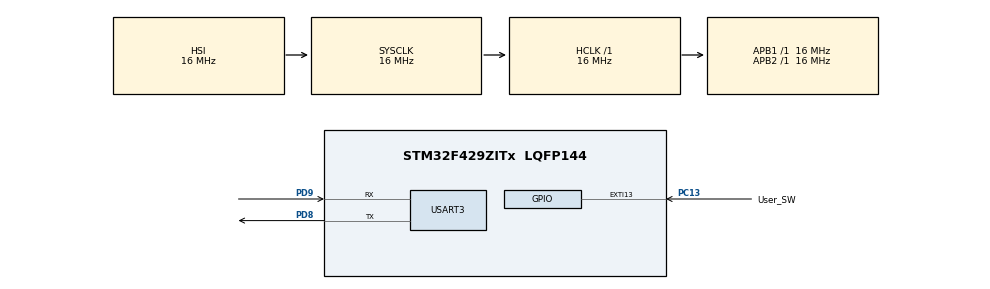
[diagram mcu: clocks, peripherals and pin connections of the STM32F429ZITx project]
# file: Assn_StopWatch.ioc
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Mcu.Family=STM32F4
Mcu.Name=STM32F429ZITx
Mcu.Package=LQFP144
NVIC.EXTI15_10_IRQn=true\:0\:0\:false\:true\:true\:2\:true\:true\:true
NVIC.PriorityGroup=NVIC_PRIORITYGROUP_4
NVIC.TIM3_IRQn=true\:0\:0\:false\:true\:true\:3\:true\:true\:true
NVIC.TIM4_IRQn=true\:0\:0\:false\:true\:true\:4\:true\:true\:true
NVIC.USART3_IRQn=true\:0\:0\:false\:true\:true\:1\:true\:true\:true
PC13.GPIO_Label=User_SW
PC13.Signal=GPXTI13
PD8.Mode=Asynchronous
PD8.Signal=USART3_TX
PD9.Mode=Asynchronous
PD9.Signal=USART3_RX
ProjectManager.HeapSize=0x200
ProjectManager.StackSize=0x400
ProjectManager.TargetToolchain=STM32CubeIDE
RCC.AHBFreq_Value=16000000
RCC.APB1Freq_Value=16000000
RCC.APB2Freq_Value=16000000
RCC.CortexFreq_Value=16000000
RCC.HSE_VALUE=25000000
RCC.HSI_VALUE=16000000
RCC.LSE_VALUE=32768
RCC.SYSCLKFreq_VALUE=16000000
RCC.VCOOutputFreq_Value=192000000
TIM3.Period=9
TIM3.Prescaler=15999
TIM4.Period=999
TIM4.Prescaler=15999
USART3.VirtualMode=VM_ASYNC
VP_TIM3_VS_ClockSourceINT.Mode=Internal
VP_TIM4_VS_ClockSourceINT.Mode=Internal
board=custom

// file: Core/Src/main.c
/* USER CODE BEGIN Header */
/**
  ******************************************************************************
  * @file           : main.c
  * @brief          : Main program body
  ******************************************************************************
  * @attention
  *
  * Copyright (c) 2024 STMicroelectronics.
  * All rights reserved.
  *
  * This software is licensed under terms that can be found in the LICENSE file
  * in the root directory of this software component.
  * If no LICENSE file comes with this software, it is provided AS-IS.
  *
  ******************************************************************************
  */
/* USER CODE END Header */
#include "main.h"

/* USER CODE BEGIN Includes */
#include <stdio.h>
#include <string.h>
/* USER CODE END Includes */

/* USER CODE BEGIN PTD */
typedef uint8_t bool;
#define true 1
#define false 0
/* USER CODE END PTD */

TIM_HandleTypeDef htim3;
TIM_HandleTypeDef htim4;

UART_HandleTypeDef huart3;

void SystemClock_Config(void);
static void MX_GPIO_Init(void);
static void MX_TIM3_Init(void);
static void MX_TIM4_Init(void);
static void MX_USART3_UART_Init(void);
static void MX_NVIC_Init(void);
/* USER CODE BEGIN PFP */
void Print_Time(void);
void Reset_Time(void);
/* USER CODE END PFP */

/* USER CODE BEGIN 0 */
uint8_t ms = 0, s = 0, m = 0, h = 0;
char tx_buf[30];
bool running = false;
bool display_time = true;
uint8_t count = 0;
char save_time[5][30];
/* USER CODE END 0 */

int main(void)
{

  /* MCU Configuration--------------------------------------------------------*/

  /* Reset of all peripherals, Initializes the Flash interface and the Systick. */
  HAL_Init();

  /* Configure the system clock */
  SystemClock_Config();

  /* Initialize all configured peripherals */
  MX_GPIO_Init();
  MX_TIM3_Init();
  MX_TIM4_Init();
  MX_USART3_UART_Init();

  /* Initialize interrupts */
  MX_NVIC_Init();

  /* Infinite loop */
  /* USER CODE BEGIN WHILE */
  Reset_Time();
  while (1)
  {
    /* USER CODE END WHILE */

  }
}

void SystemClock_Config(void)
{
  RCC_OscInitTypeDef RCC_OscInitStruct = {0};
  RCC_ClkInitTypeDef RCC_ClkInitStruct = {0};

  /** Configure the main internal regulator output voltage
  */
  __HAL_RCC_PWR_CLK_ENABLE();
  __HAL_PWR_VOLTAGESCALING_CONFIG(PWR_REGULATOR_VOLTAGE_SCALE3);

  /** Initializes the RCC Oscillators according to the specified parameters
  * in the RCC_OscInitTypeDef structure.
  */
  RCC_OscInitStruct.OscillatorType = RCC_OSCILLATORTYPE_HSI;
  RCC_OscInitStruct.HSIState = RCC_HSI_ON;
  RCC_OscInitStruct.HSICalibrationValue = RCC_HSICALIBRATION_DEFAULT;
  RCC_OscInitStruct.PLL.PLLState = RCC_PLL_NONE;
  if (HAL_RCC_OscConfig(&RCC_OscInitStruct) != HAL_OK)
  {
    Error_Handler();
  }

  /** Initializes the CPU, AHB and APB buses clocks
  */
  RCC_ClkInitStruct.ClockType = RCC_CLOCKTYPE_HCLK|RCC_CLOCKTYPE_SYSCLK
                              |RCC_CLOCKTYPE_PCLK1|RCC_CLOCKTYPE_PCLK2;
  RCC_ClkInitStruct.SYSCLKSource = RCC_SYSCLKSOURCE_HSI;
  RCC_ClkInitStruct.AHBCLKDivider = RCC_SYSCLK_DIV1;
  RCC_ClkInitStruct.APB1CLKDivider = RCC_HCLK_DIV1;
  RCC_ClkInitStruct.APB2CLKDivider = RCC_HCLK_DIV1;

  if (HAL_RCC_ClockConfig(&RCC_ClkInitStruct, FLASH_LATENCY_0) != HAL_OK)
  {
    Error_Handler();
  }
}

/**
  * @brief NVIC Configuration.
  * @retval None
  */
static void MX_NVIC_Init(void)
{
  /* USART3_IRQn interrupt configuration */
  HAL_NVIC_SetPriority(USART3_IRQn, 0, 0);
  HAL_NVIC_EnableIRQ(USART3_IRQn);
  /* EXTI15_10_IRQn interrupt configuration */
  HAL_NVIC_SetPriority(EXTI15_10_IRQn, 0, 0);
  HAL_NVIC_EnableIRQ(EXTI15_10_IRQn);
  /* TIM3_IRQn interrupt configuration */
  HAL_NVIC_SetPriority(TIM3_IRQn, 0, 0);
  HAL_NVIC_EnableIRQ(TIM3_IRQn);
  /* TIM4_IRQn interrupt configuration */
  HAL_NVIC_SetPriority(TIM4_IRQn, 0, 0);
  HAL_NVIC_EnableIRQ(TIM4_IRQn);
}

static void MX_TIM3_Init(void)
{

  TIM_ClockConfigTypeDef sClockSourceConfig = {0};
  TIM_MasterConfigTypeDef sMasterConfig = {0};

  htim3.Instance = TIM3;
  htim3.Init.Prescaler = 15999;
  htim3.Init.CounterMode = TIM_COUNTERMODE_UP;
  htim3.Init.Period = 9;
  htim3.Init.ClockDivision = TIM_CLOCKDIVISION_DIV1;
  htim3.Init.AutoReloadPreload = TIM_AUTORELOAD_PRELOAD_DISABLE;
  if (HAL_TIM_Base_Init(&htim3) != HAL_OK)
  {
    Error_Handler();
  }
  sClockSourceConfig.ClockSource = TIM_CLOCKSOURCE_INTERNAL;
  if (HAL_TIM_ConfigClockSource(&htim3, &sClockSourceConfig) != HAL_OK)
  {
    Error_Handler();
  }
  sMasterConfig.MasterOutputTrigger = TIM_TRGO_RESET;
  sMasterConfig.MasterSlaveMode = TIM_MASTERSLAVEMODE_DISABLE;
  if (HAL_TIMEx_MasterConfigSynchronization(&htim3, &sMasterConfig) != HAL_OK)
  {
    Error_Handler();
  }

}

static void MX_TIM4_Init(void)
{

  TIM_ClockConfigTypeDef sClockSourceConfig = {0};
  TIM_MasterConfigTypeDef sMasterConfig = {0};

  htim4.Instance = TIM4;
  htim4.Init.Prescaler = 15999;
  htim4.Init.CounterMode = TIM_COUNTERMODE_UP;
  htim4.Init.Period = 999;
  htim4.Init.ClockDivision = TIM_CLOCKDIVISION_DIV1;
  htim4.Init.AutoReloadPreload = TIM_AUTORELOAD_PRELOAD_DISABLE;
  if (HAL_TIM_Base_Init(&htim4) != HAL_OK)
  {
    Error_Handler();
  }
  sClockSourceConfig.ClockSource = TIM_CLOCKSOURCE_INTERNAL;
  if (HAL_TIM_ConfigClockSource(&htim4, &sClockSourceConfig) != HAL_OK)
  {
    Error_Handler();
  }
  sMasterConfig.MasterOutputTrigger = TIM_TRGO_RESET;
  sMasterConfig.MasterSlaveMode = TIM_MASTERSLAVEMODE_DISABLE;
  if (HAL_TIMEx_MasterConfigSynchronization(&htim4, &sMasterConfig) != HAL_OK)
  {
    Error_Handler();
  }

}

static void MX_USART3_UART_Init(void)
{

  huart3.Instance = USART3;
  huart3.Init.BaudRate = 115200;
  huart3.Init.WordLength = UART_WORDLENGTH_8B;
  huart3.Init.StopBits = UART_STOPBITS_1;
  huart3.Init.Parity = UART_PARITY_NONE;
  huart3.Init.Mode = UART_MODE_TX_RX;
  huart3.Init.HwFlowCtl = UART_HWCONTROL_NONE;
  huart3.Init.OverSampling = UART_OVERSAMPLING_16;
  if (HAL_UART_Init(&huart3) != HAL_OK)
  {
    Error_Handler();
  }

}

static void MX_GPIO_Init(void)
{
  GPIO_InitTypeDef GPIO_InitStruct = {0};

  /* GPIO Ports Clock Enable */
  __HAL_RCC_GPIOC_CLK_ENABLE();
  __HAL_RCC_GPIOD_CLK_ENABLE();

  /*Configure GPIO pin : User_SW_Pin */
  GPIO_InitStruct.Pin = User_SW_Pin;
  GPIO_InitStruct.Mode = GPIO_MODE_IT_RISING;
  GPIO_InitStruct.Pull = GPIO_NOPULL;
  HAL_GPIO_Init(User_SW_GPIO_Port, &GPIO_InitStruct);

}

/* USER CODE BEGIN 4 */
void Print_Time(void)
{
	sprintf(tx_buf, "%02d:%02d:%02d:%02d\r", h, m, s, ms);
	HAL_UART_Transmit(&huart3, (uint8_t*)tx_buf, strlen(tx_buf), 100);
}

void Reset_Time(void)
{
	ms = s = m = h = 0;
	running = false;
	display_time = true;
	count = 0;
	memset(save_time, 0, sizeof(save_time));
	HAL_UART_Transmit(&huart3, (uint8_t*)"\r\n", 2, 100); // Send a new line
	Print_Time();
}

void HAL_GPIO_EXTI_Callback(uint16_t GPIO_Pin)
{
	if(GPIO_Pin == User_SW_Pin) {
		if(!running) { //타이머가 동작 중이 아니라면
			HAL_TIM_Base_Start_IT(&htim3);
			running = true; //타이머 동작 상태 설정
		}
		else { //타이머가 동작 중이라면
			if(count < 5) {
				sprintf(save_time[count], "%d번 >> %02d:%02d:%02d:%02d\r\n", count + 1, h, m, s, ms);
				count++;
			}
			if(count == 5) {
				for(int i = 0; i < count; i++) {
					HAL_UART_Transmit(&huart3, (uint8_t*)save_time[i], strlen(save_time[i]), 100);
				}
				HAL_TIM_Base_Stop_IT(&htim3);
				Reset_Time();
			}
			else {
				display_time = false; //시간 표시 중지
				HAL_TIM_Base_Start_IT(&htim4);
			}
		}
	}
}

void HAL_TIM_PeriodElapsedCallback(TIM_HandleTypeDef *htim)
{
	if(htim->Instance == TIM3) {
		ms++;
		if(ms == 100) {
			ms = 0; s++;
		}
		else if(s == 60) {
			s = 0; m++;
		}
		else if(m == 60) {
			m = 0; h++;
		}
		if(display_time) Print_Time(); //시간 표시 상태가 true일 때만 출력
	}
	else if(htim->Instance == TIM4) {
		HAL_TIM_Base_Stop_IT(&htim4);
		display_time = true; //시간 표시 재개
	}
}
/* USER CODE END 4 */

void Error_Handler(void)
{
  __disable_irq();
  while (1)
  {
  }
}
